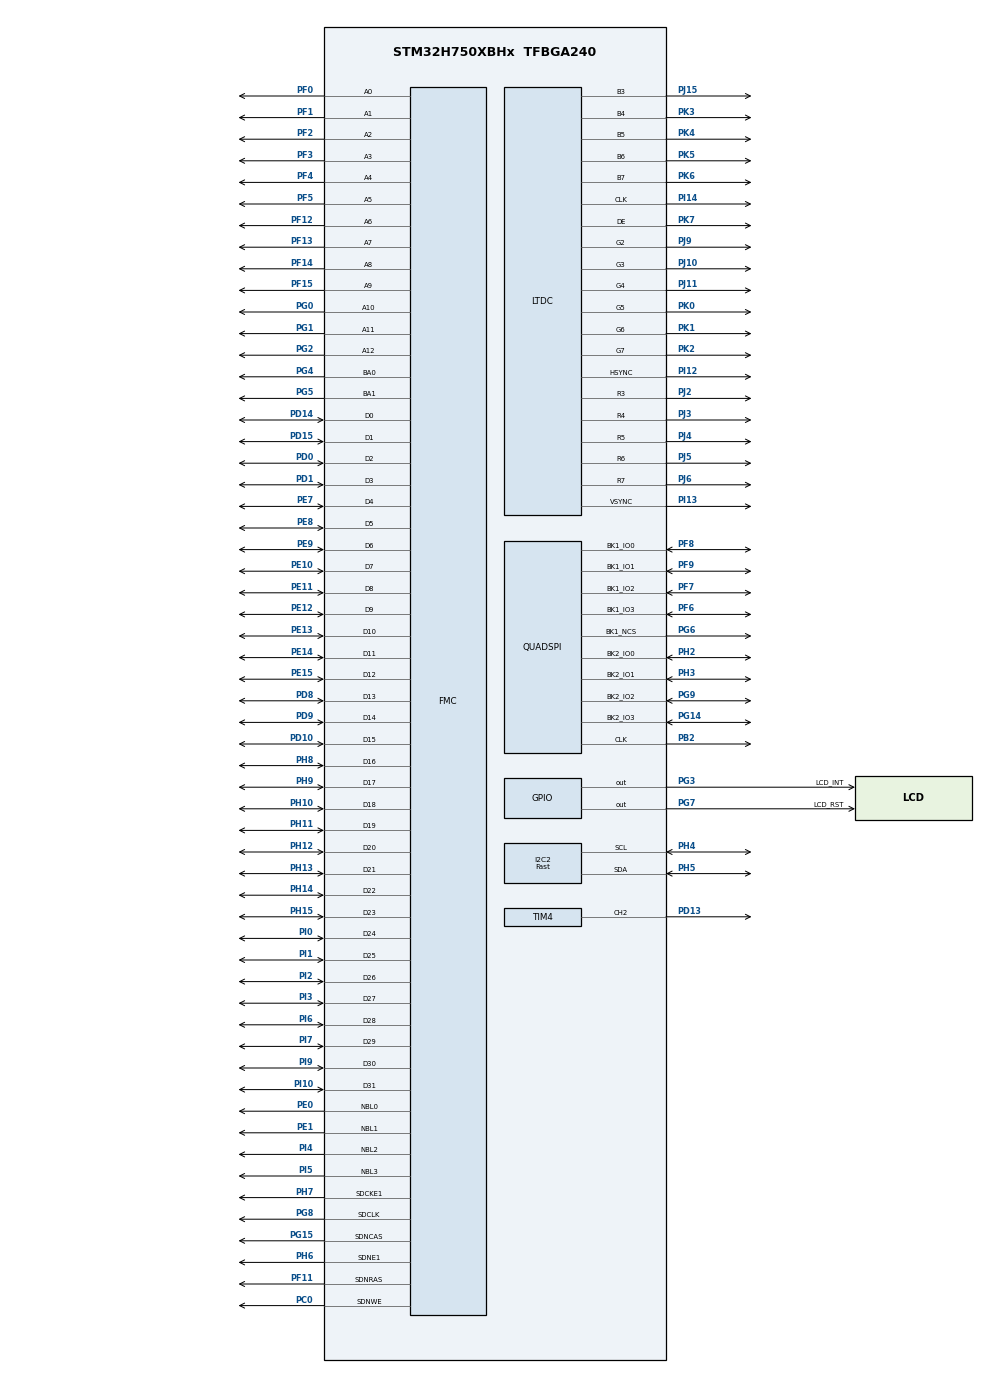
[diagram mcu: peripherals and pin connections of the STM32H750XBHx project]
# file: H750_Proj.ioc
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CORTEX_M7.AccessPermission-Cortex_Memory_Protection_Unit_Region0_Settings=MPU_REGION_FULL_ACCESS
CORTEX_M7.AccessPermission-Cortex_Memory_Protection_Unit_Region1_Settings=MPU_REGION_FULL_ACCESS
CORTEX_M7.AccessPermission-Cortex_Memory_Protection_Unit_Region2_Settings=MPU_REGION_FULL_ACCESS
CORTEX_M7.AccessPermission-Cortex_Memory_Protection_Unit_Region3_Settings=MPU_REGION_FULL_ACCESS
CORTEX_M7.AccessPermission-Cortex_Memory_Protection_Unit_Region4_Settings=MPU_REGION_FULL_ACCESS
CORTEX_M7.AccessPermission-Cortex_Memory_Protection_Unit_Region5_Settings=MPU_REGION_FULL_ACCESS
CORTEX_M7.BaseAddress-Cortex_Memory_Protection_Unit_Region0_Settings=0x20000000
CORTEX_M7.BaseAddress-Cortex_Memory_Protection_Unit_Region1_Settings=0x24000000
CORTEX_M7.BaseAddress-Cortex_Memory_Protection_Unit_Region2_Settings=0x0
CORTEX_M7.BaseAddress-Cortex_Memory_Protection_Unit_Region3_Settings=0x38000000
CORTEX_M7.BaseAddress-Cortex_Memory_Protection_Unit_Region4_Settings=0x60000000
CORTEX_M7.BaseAddress-Cortex_Memory_Protection_Unit_Region5_Settings=0xD0000000
CORTEX_M7.CPU_DCache=Enabled
CORTEX_M7.CPU_ICache=Enabled
CORTEX_M7.Enable-Cortex_Memory_Protection_Unit_Region0_Settings=MPU_REGION_ENABLE
CORTEX_M7.Enable-Cortex_Memory_Protection_Unit_Region1_Settings=MPU_REGION_ENABLE
CORTEX_M7.Enable-Cortex_Memory_Protection_Unit_Region2_Settings=MPU_REGION_ENABLE
CORTEX_M7.Enable-Cortex_Memory_Protection_Unit_Region3_Settings=MPU_REGION_ENABLE
CORTEX_M7.Enable-Cortex_Memory_Protection_Unit_Region4_Settings=MPU_REGION_ENABLE
CORTEX_M7.Enable-Cortex_Memory_Protection_Unit_Region5_Settings=MPU_REGION_ENABLE
CORTEX_M7.IsBufferable-Cortex_Memory_Protection_Unit_Region0_Settings=MPU_ACCESS_BUFFERABLE
CORTEX_M7.IsBufferable-Cortex_Memory_Protection_Unit_Region1_Settings=MPU_ACCESS_BUFFERABLE
CORTEX_M7.IsBufferable-Cortex_Memory_Protection_Unit_Region2_Settings=MPU_ACCESS_BUFFERABLE
CORTEX_M7.IsBufferable-Cortex_Memory_Protection_Unit_Region3_Settings=MPU_ACCESS_BUFFERABLE
CORTEX_M7.IsBufferable-Cortex_Memory_Protection_Unit_Region5_Settings=MPU_ACCESS_BUFFERABLE
CORTEX_M7.IsCacheable-Cortex_Memory_Protection_Unit_Region0_Settings=MPU_ACCESS_CACHEABLE
CORTEX_M7.IsCacheable-Cortex_Memory_Protection_Unit_Region1_Settings=MPU_ACCESS_CACHEABLE
CORTEX_M7.IsCacheable-Cortex_Memory_Protection_Unit_Region2_Settings=MPU_ACCESS_CACHEABLE
CORTEX_M7.IsCacheable-Cortex_Memory_Protection_Unit_Region5_Settings=MPU_ACCESS_CACHEABLE
CORTEX_M7.MPU_Control=MPU_PRIVILEGED_DEFAULT
CORTEX_M7.Size-Cortex_Memory_Protection_Unit_Region0_Settings=MPU_REGION_SIZE_128KB
CORTEX_M7.Size-Cortex_Memory_Protection_Unit_Region1_Settings=MPU_REGION_SIZE_512KB
CORTEX_M7.Size-Cortex_Memory_Protection_Unit_Region2_Settings=MPU_REGION_SIZE_512KB
CORTEX_M7.Size-Cortex_Memory_Protection_Unit_Region3_Settings=MPU_REGION_SIZE_64KB
CORTEX_M7.Size-Cortex_Memory_Protection_Unit_Region4_Settings=MPU_REGION_SIZE_64MB
CORTEX_M7.Size-Cortex_Memory_Protection_Unit_Region5_Settings=MPU_REGION_SIZE_64MB
DMA2D.ColorMode=DMA2D_OUTPUT_RGB565
FMC.CASLatency1=FMC_SDRAM_CAS_LATENCY_3
FMC.ColumnBitsNumber1=FMC_SDRAM_COLUMN_BITS_NUM_9
FMC.ExitSelfRefreshDelay1=8
FMC.LoadToActiveDelay1=2
FMC.RCDDelay1=2
FMC.RPDelay1=2
FMC.RPDelay2=2
FMC.ReadBurst1=FMC_SDRAM_RBURST_ENABLE
FMC.ReadBurst2=FMC_SDRAM_RBURST_ENABLE
FMC.ReadPipeDelay1=FMC_SDRAM_RPIPE_DELAY_1
FMC.ReadPipeDelay2=FMC_SDRAM_RPIPE_DELAY_1
FMC.RowCycleDelay1=8
FMC.RowCycleDelay2=8
FMC.SDClockPeriod1=FMC_SDRAM_CLOCK_PERIOD_2
FMC.SDClockPeriod2=FMC_SDRAM_CLOCK_PERIOD_2
FMC.SelfRefreshTime1=5
FMC.WriteRecoveryTime1=4
FREERTOS.Queues01=GuiQueue,16,uint16_t,0,Dynamic,NULL,NULL;myQueue,16,uint16_t,0,Dynamic,NULL,NULL
FREERTOS.Tasks01=defaultTask,0,2048,StartDefaultTask,Default,NULL,Dynamic,NULL,NULL;MessageTask,0,512,StartMessageTask,Default,NULL,Dynamic,NULL,NULL
FREERTOS.configTOTAL_HEAP_SIZE=32768
FREERTOS.configUSE_APPLICATION_TASK_TAG=1
I2C2.I2C_Speed_Mode=I2C_Fast
I2C2.Timing=0x00B03FDB
LTDC.ActiveW=480
LTDC.Alpha_L0=255
LTDC.FBStartAdress_L0=0xD0000000
LTDC.HBP=43
LTDC.HFP=8
LTDC.HSync=2
LTDC.ImageHeight_L0=480
LTDC.ImageWidth_L0=480
LTDC.Layers=0
LTDC.PCPolarity=LTDC_PCPOLARITY_IIPC
LTDC.PixelFormat_L0=LTDC_PIXEL_FORMAT_RGB565
LTDC.VBP=15
LTDC.VFP=12
LTDC.VSync=10
LTDC.WindowX1_L0=480
LTDC.WindowY1_L0=480
Mcu.Family=STM32H7
Mcu.Name=STM32H750XBHx
Mcu.Package=TFBGA240
NVIC.DMA2D_IRQn=true\:5\:0\:false\:false\:true\:true\:true\:true
NVIC.LTDC_IRQn=true\:5\:0\:false\:false\:true\:true\:true\:true
NVIC.PriorityGroup=NVIC_PRIORITYGROUP_4
NVIC.QUADSPI_IRQn=true\:5\:0\:false\:false\:true\:true\:true\:true
NVIC.TIM7_IRQn=true\:0\:0\:false\:false\:true\:false\:false\:true
NVIC.TimeBase=TIM7_IRQn
NVIC.TimeBaseIP=TIM7
PB2.GPIO_Speed=GPIO_SPEED_FREQ_VERY_HIGH
PB2.Mode=Dual_Bank
PB2.Signal=QUADSPI_CLK
PB2.Stacked=true
PC0.Signal=FMC_SDNWE
PC0.Stacked=true
PD0.Signal=FMC_D2_DA2
PD0.Stacked=true
PD1.Signal=FMC_D3_DA3
PD1.Stacked=true
PD10.Signal=FMC_D15_DA15
PD10.Stacked=true
PD13.Signal=S_TIM4_CH2
PD14.Signal=FMC_D0_DA0
PD14.Stacked=true
PD15.Signal=FMC_D1_DA1
PD15.Stacked=true
PD8.Signal=FMC_D13_DA13
PD8.Stacked=true
PD9.Signal=FMC_D14_DA14
PD9.Stacked=true
PE0.Signal=FMC_NBL0
PE0.Stacked=true
PE1.Signal=FMC_NBL1
PE1.Stacked=true
PE10.Signal=FMC_D7_DA7
PE10.Stacked=true
PE11.Signal=FMC_D8_DA8
PE11.Stacked=true
PE12.Signal=FMC_D9_DA9
PE12.Stacked=true
PE13.Signal=FMC_D10_DA10
PE13.Stacked=true
PE14.Signal=FMC_D11_DA11
PE14.Stacked=true
PE15.Signal=FMC_D12_DA12
PE15.Stacked=true
PE7.Signal=FMC_D4_DA4
PE7.Stacked=true
PE8.Signal=FMC_D5_DA5
PE8.Stacked=true
PE9.Signal=FMC_D6_DA6
PE9.Stacked=true
PF0.Signal=FMC_A0
PF0.Stacked=true
PF1.Signal=FMC_A1
PF1.Stacked=true
PF11.Signal=FMC_SDNRAS
PF11.Stacked=true
PF12.Signal=FMC_A6
PF12.Stacked=true
PF13.Signal=FMC_A7
PF13.Stacked=true
PF14.Signal=FMC_A8
PF14.Stacked=true
PF15.Signal=FMC_A9
PF15.Stacked=true
PF2.Signal=FMC_A2
PF2.Stacked=true
PF3.Signal=FMC_A3
PF3.Stacked=true
PF4.Signal=FMC_A4
PF4.Stacked=true
PF5.Signal=FMC_A5
PF5.Stacked=true
PF6.GPIO_Speed=GPIO_SPEED_FREQ_VERY_HIGH
PF6.Mode=Dual_Bank
PF6.Signal=QUADSPI_BK1_IO3
PF6.Stacked=true
PF7.GPIO_Speed=GPIO_SPEED_FREQ_VERY_HIGH
PF7.Mode=Dual_Bank
PF7.Signal=QUADSPI_BK1_IO2
PF7.Stacked=true
PF8.GPIO_Speed=GPIO_SPEED_FREQ_VERY_HIGH
PF8.Mode=Dual_Bank
PF8.Signal=QUADSPI_BK1_IO0
PF8.Stacked=true
PF9.GPIO_Speed=GPIO_SPEED_FREQ_VERY_HIGH
PF9.Mode=Dual_Bank
PF9.Signal=QUADSPI_BK1_IO1
PF9.Stacked=true
PG0.Signal=FMC_A10
PG0.Stacked=true
PG1.Signal=FMC_A11
PG1.Stacked=true
PG14.GPIO_Speed=GPIO_SPEED_FREQ_VERY_HIGH
PG14.Mode=Dual_Bank
PG14.Signal=QUADSPI_BK2_IO3
PG14.Stacked=true
PG15.Signal=FMC_SDNCAS
PG15.Stacked=true
PG2.Signal=FMC_A12
PG2.Stacked=true
PG3.GPIO_Label=LCD_INT
PG3.Signal=GPIO_Output
PG4.Signal=FMC_A14_BA0
PG4.Stacked=true
PG5.Signal=FMC_A15_BA1
PG5.Stacked=true
PG6.GPIO_Speed=GPIO_SPEED_FREQ_VERY_HIGH
PG6.Mode=Enable Chip Select 1 for both banks
PG6.Signal=QUADSPI_BK1_NCS
PG6.Stacked=true
PG7.GPIO_Label=LCD_RST
PG7.Signal=GPIO_Output
PG8.Signal=FMC_SDCLK
PG8.Stacked=true
PG9.GPIO_Speed=GPIO_SPEED_FREQ_VERY_HIGH
PG9.Mode=Dual_Bank
PG9.Signal=QUADSPI_BK2_IO2
PG9.Stacked=true
PH0-OSC_IN\ (PH0).Mode=HSE-External-Oscillator
PH0-OSC_IN\ (PH0).Signal=RCC_OSC_IN
PH1-OSC_OUT\ (PH1).Mode=HSE-External-Oscillator
PH1-OSC_OUT\ (PH1).Signal=RCC_OSC_OUT
PH10.Signal=FMC_D18
PH10.Stacked=true
PH11.Signal=FMC_D19
PH11.Stacked=true
PH12.Signal=FMC_D20
PH12.Stacked=true
PH13.Signal=FMC_D21
PH14.Signal=FMC_D22
PH15.Signal=FMC_D23
PH2.GPIO_Speed=GPIO_SPEED_FREQ_VERY_HIGH
PH2.Mode=Dual_Bank
PH2.Signal=QUADSPI_BK2_IO0
PH2.Stacked=true
PH3.GPIO_Speed=GPIO_SPEED_FREQ_VERY_HIGH
PH3.Mode=Dual_Bank
PH3.Signal=QUADSPI_BK2_IO1
PH3.Stacked=true
PH4.Mode=I2C
PH4.Signal=I2C2_SCL
PH5.Mode=I2C
PH5.Signal=I2C2_SDA
PH6.Mode=SdramChipSelect2_1
PH6.Signal=FMC_SDNE1
PH6.Stacked=true
PH7.Mode=SdramChipSelect2_1
PH7.Signal=FMC_SDCKE1
PH7.Stacked=true
PH8.Signal=FMC_D16
PH8.Stacked=true
PH9.Signal=FMC_D17
PH9.Stacked=true
PI0.Signal=FMC_D24
PI1.Signal=FMC_D25
PI10.Signal=FMC_D31
PI12.Mode=RGB565
PI12.Signal=LTDC_HSYNC
PI12.Stacked=true
PI13.Mode=RGB565
PI13.Signal=LTDC_VSYNC
PI13.Stacked=true
PI14.Mode=RGB565
PI14.Signal=LTDC_CLK
PI14.Stacked=true
PI2.Signal=FMC_D26
PI3.Signal=FMC_D27
PI4.Signal=FMC_NBL2
PI4.Stacked=true
PI5.Signal=FMC_NBL3
PI5.Stacked=true
PI6.Signal=FMC_D28
PI7.Signal=FMC_D29
PI9.Signal=FMC_D30
PJ10.Mode=RGB565
PJ10.Signal=LTDC_G3
PJ10.Stacked=true
PJ11.Mode=RGB565
PJ11.Signal=LTDC_G4
PJ11.Stacked=true
PJ15.Mode=RGB565
PJ15.Signal=LTDC_B3
PJ15.Stacked=true
PJ2.Mode=RGB565
PJ2.Signal=LTDC_R3
PJ2.Stacked=true
PJ3.Mode=RGB565
PJ3.Signal=LTDC_R4
PJ3.Stacked=true
PJ4.Mode=RGB565
PJ4.Signal=LTDC_R5
PJ4.Stacked=true
PJ5.Mode=RGB565
PJ5.Signal=LTDC_R6
PJ5.Stacked=true
PJ6.Mode=RGB565
PJ6.Signal=LTDC_R7
PJ6.Stacked=true
PJ9.Mode=RGB565
PJ9.Signal=LTDC_G2
PJ9.Stacked=true
PK0.Mode=RGB565
PK0.Signal=LTDC_G5
PK0.Stacked=true
PK1.Mode=RGB565
PK1.Signal=LTDC_G6
PK1.Stacked=true
PK2.Mode=RGB565
PK2.Signal=LTDC_G7
PK2.Stacked=true
PK3.Mode=RGB565
PK3.Signal=LTDC_B4
PK3.Stacked=true
PK4.Mode=RGB565
PK4.Signal=LTDC_B5
PK4.Stacked=true
PK5.Mode=RGB565
PK5.Signal=LTDC_B6
PK5.Stacked=true
PK6.Mode=RGB565
PK6.Signal=LTDC_B7
PK6.Stacked=true
PK7.Mode=RGB565
PK7.Signal=LTDC_DE
PK7.Stacked=true
ProjectManager.HeapSize=0x400
ProjectManager.StackSize=0x800
ProjectManager.TargetToolchain=MDK-ARM V5.27
QUADSPI.ChipSelectHighTime=QSPI_CS_HIGH_TIME_4_CYCLE
QUADSPI.ClockPrescaler=2
QUADSPI.FifoThreshold=8
QUADSPI.FlashSize=25
QUADSPI.SampleShifting=QSPI_SAMPLE_SHIFTING_NONE
RCC.ADCFreq_Value=50390625
RCC.APB1Freq_Value=120000000
RCC.APB2Freq_Value=120000000
RCC.APB3Freq_Value=120000000
RCC.APB4Freq_Value=120000000
RCC.CortexFreq_Value=480000000
RCC.D1PPRE=RCC_APB3_DIV2
RCC.D2PPRE1=RCC_APB1_DIV2
RCC.D2PPRE2=RCC_APB2_DIV2
RCC.D3PPRE=RCC_APB4_DIV2
RCC.DIVM1=5
RCC.DIVM3=31
RCC.DIVN1=192
RCC.DIVN3=138
RCC.DIVR3=6
RCC.HCLKFreq_Value=240000000
RCC.HPRE=RCC_HCLK_DIV2
RCC.PLLSourceVirtual=RCC_PLLSOURCE_HSE
RCC.SYSCLKFreq_VALUE=480000000
RCC.SYSCLKSource=RCC_SYSCLKSOURCE_PLLCLK
RCC.USBFreq_Value=480000000
SH.FMC_A0.0=FMC_A0,13b-sda1
SH.FMC_A1.0=FMC_A1,13b-sda1
SH.FMC_A10.0=FMC_A10,13b-sda1
SH.FMC_A11.0=FMC_A11,13b-sda1
SH.FMC_A12.0=FMC_A12,13b-sda1
SH.FMC_A14_BA0.0=FMC_BA0,FourSdramBanks1
SH.FMC_A15_BA1.0=FMC_BA1,FourSdramBanks1
SH.FMC_A2.0=FMC_A2,13b-sda1
SH.FMC_A3.0=FMC_A3,13b-sda1
SH.FMC_A4.0=FMC_A4,13b-sda1
SH.FMC_A5.0=FMC_A5,13b-sda1
SH.FMC_A6.0=FMC_A6,13b-sda1
SH.FMC_A7.0=FMC_A7,13b-sda1
SH.FMC_A8.0=FMC_A8,13b-sda1
SH.FMC_A9.0=FMC_A9,13b-sda1
SH.FMC_D0_DA0.0=FMC_D0,sd-32b-d1
SH.FMC_D10_DA10.0=FMC_D10,sd-32b-d1
SH.FMC_D11_DA11.0=FMC_D11,sd-32b-d1
SH.FMC_D12_DA12.0=FMC_D12,sd-32b-d1
SH.FMC_D13_DA13.0=FMC_D13,sd-32b-d1
SH.FMC_D14_DA14.0=FMC_D14,sd-32b-d1
SH.FMC_D15_DA15.0=FMC_D15,sd-32b-d1
SH.FMC_D16.0=FMC_D16,sd-32b-d1
SH.FMC_D17.0=FMC_D17,sd-32b-d1
SH.FMC_D18.0=FMC_D18,sd-32b-d1
SH.FMC_D19.0=FMC_D19,sd-32b-d1
SH.FMC_D1_DA1.0=FMC_D1,sd-32b-d1
SH.FMC_D20.0=FMC_D20,sd-32b-d1
SH.FMC_D21.0=FMC_D21,sd-32b-d1
SH.FMC_D22.0=FMC_D22,sd-32b-d1
SH.FMC_D23.0=FMC_D23,sd-32b-d1
SH.FMC_D24.0=FMC_D24,sd-32b-d1
SH.FMC_D25.0=FMC_D25,sd-32b-d1
SH.FMC_D26.0=FMC_D26,sd-32b-d1
SH.FMC_D27.0=FMC_D27,sd-32b-d1
SH.FMC_D28.0=FMC_D28,sd-32b-d1
SH.FMC_D29.0=FMC_D29,sd-32b-d1
SH.FMC_D2_DA2.0=FMC_D2,sd-32b-d1
SH.FMC_D30.0=FMC_D30,sd-32b-d1
SH.FMC_D31.0=FMC_D31,sd-32b-d1
SH.FMC_D3_DA3.0=FMC_D3,sd-32b-d1
SH.FMC_D4_DA4.0=FMC_D4,sd-32b-d1
SH.FMC_D5_DA5.0=FMC_D5,sd-32b-d1
SH.FMC_D6_DA6.0=FMC_D6,sd-32b-d1
SH.FMC_D7_DA7.0=FMC_D7,sd-32b-d1
SH.FMC_D8_DA8.0=FMC_D8,sd-32b-d1
SH.FMC_D9_DA9.0=FMC_D9,sd-32b-d1
SH.FMC_NBL0.0=FMC_NBL0,Sd4ByteEnable1
SH.FMC_NBL1.0=FMC_NBL1,Sd4ByteEnable1
SH.FMC_NBL2.0=FMC_NBL2,Sd4ByteEnable1
SH.FMC_NBL3.0=FMC_NBL3,Sd4ByteEnable1
SH.FMC_SDCLK.0=FMC_SDCLK,13b-sda1
SH.FMC_SDNCAS.0=FMC_SDNCAS,13b-sda1
SH.FMC_SDNRAS.0=FMC_SDNRAS,13b-sda1
SH.FMC_SDNWE.0=FMC_SDNWE,13b-sda1
SH.S_TIM4_CH2.0=TIM4_CH2,PWM Generation2 CH2
STMicroelectronics.X-CUBE-TOUCHGFX.4.13.0.ApplicationCcGraphicsJjApplication=TouchGFXOoGenerator
STMicroelectronics.X-CUBE-TOUCHGFX.4.13.0.tgfx_address1=0xD0000000
STMicroelectronics.X-CUBE-TOUCHGFX.4.13.0.tgfx_address2=0xD0070800
STMicroelectronics.X-CUBE-TOUCHGFX.4.13.0.tgfx_buffering_strategy=Double
STMicroelectronics.X-CUBE-TOUCHGFX.4.13.0.tgfx_display_interface=disp_ltdc
STMicroelectronics.X-CUBE-TOUCHGFX.4.13.0.tgfx_hardware_accelerator=dma_2d
STMicroelectronics.X-CUBE-TOUCHGFX.4.13.0.tgfx_location=By Address
STMicroelectronics.X-CUBE-TOUCHGFX.4.13.0.tgfx_vsync=vsync_ltdc
TIM4.Channel-PWM\ Generation2\ CH2=TIM_CHANNEL_2
TIM4.OCPolarity_2=TIM_OCPOLARITY_LOW
TIM4.Period=999
TIM4.Prescaler=2399
VP_CRC_VS_CRC.Mode=CRC_Activate
VP_DMA2D_VS_DMA2D.Mode=DMA2D_Activate
VP_FREERTOS_VS_CMSIS_V1.Mode=CMSIS_V1
VP_STMicroelectronics.X-CUBE-TOUCHGFX_VS_GraphicsJjApplication_4.13.0.Mode=GraphicsJjApplication
VP_SYS_VS_tim7.Mode=TIM7
VP_TIM4_VS_ClockSourceINT.Mode=Internal
board=custom

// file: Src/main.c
/* USER CODE BEGIN Header */
/**
  ******************************************************************************
  * @file           : main.c
  * @brief          : Main program body
  ******************************************************************************
  * @attention
  *
  * <h2><center>&copy; Copyright (c) 2020 STMicroelectronics.
  * All rights reserved.</center></h2>
  *
  * This software component is licensed by ST under Ultimate Liberty license
  * SLA0044, the "License"; You may not use this file except in compliance with
  * the License. You may obtain a copy of the License at:
  *                             www.st.com/SLA0044
  *
  ******************************************************************************
  */
/* USER CODE END Header */

#include "main.h"
#include "cmsis_os.h"
#include "crc.h"
#include "dma2d.h"
#include "i2c.h"
#include "ltdc.h"
#include "quadspi.h"
#include "tim.h"
#include "gpio.h"
#include "fmc.h"
#include "app_touchgfx.h"

void SystemClock_Config(void);
static void MPU_Config(void);
void MX_FREERTOS_Init(void);

int main(void)
{

  /* MPU Configuration--------------------------------------------------------*/
  MPU_Config();

  /* Enable I-Cache---------------------------------------------------------*/
  SCB_EnableICache();

  /* Enable D-Cache---------------------------------------------------------*/
  SCB_EnableDCache();

  /* MCU Configuration--------------------------------------------------------*/

  /* Reset of all peripherals, Initializes the Flash interface and the Systick. */
  HAL_Init();

  /* Configure the system clock */
  SystemClock_Config();

  /* Initialize all configured peripherals */
  MX_GPIO_Init();
  MX_CRC_Init();
  MX_DMA2D_Init();
  MX_FMC_Init();
  MX_I2C2_Init();
  MX_LTDC_Init();
  MX_QUADSPI_Init();
  MX_TIM4_Init();
  MX_TouchGFX_Init();
  /* USER CODE BEGIN 2 */
  SDRAM_InitSequence();

  HAL_GPIO_WritePin(GPIOG, LCD_RST_Pin, GPIO_PIN_SET);
  HAL_TIM_PWM_Start(&htim4,TIM_CHANNEL_2);
  __HAL_TIM_SET_COMPARE(&htim4,TIM_CHANNEL_2, 500);

  /* USER CODE END 2 */

  /* Call init function for freertos objects (in freertos.c) */
  MX_FREERTOS_Init();
  /* Start scheduler */
  osKernelStart();

  /* We should never get here as control is now taken by the scheduler */
  /* Infinite loop */
  while (1)
  {

  }
}

void SystemClock_Config(void)
{
  RCC_OscInitTypeDef RCC_OscInitStruct = {0};
  RCC_ClkInitTypeDef RCC_ClkInitStruct = {0};
  RCC_PeriphCLKInitTypeDef PeriphClkInitStruct = {0};

  /** Supply configuration update enable
  */
  HAL_PWREx_ConfigSupply(PWR_LDO_SUPPLY);
  /** Configure the main internal regulator output voltage
  */
  __HAL_PWR_VOLTAGESCALING_CONFIG(PWR_REGULATOR_VOLTAGE_SCALE0);

  while(!__HAL_PWR_GET_FLAG(PWR_FLAG_VOSRDY)) {}
  /** Macro to configure the PLL clock source
  */
  __HAL_RCC_PLL_PLLSOURCE_CONFIG(RCC_PLLSOURCE_HSE);
  /** Initializes the CPU, AHB and APB busses clocks
  */
  RCC_OscInitStruct.OscillatorType = RCC_OSCILLATORTYPE_HSE;
  RCC_OscInitStruct.HSEState = RCC_HSE_ON;
  RCC_OscInitStruct.PLL.PLLState = RCC_PLL_ON;
  RCC_OscInitStruct.PLL.PLLSource = RCC_PLLSOURCE_HSE;
  RCC_OscInitStruct.PLL.PLLM = 5;
  RCC_OscInitStruct.PLL.PLLN = 192;
  RCC_OscInitStruct.PLL.PLLP = 2;
  RCC_OscInitStruct.PLL.PLLQ = 2;
  RCC_OscInitStruct.PLL.PLLR = 2;
  RCC_OscInitStruct.PLL.PLLRGE = RCC_PLL1VCIRANGE_2;
  RCC_OscInitStruct.PLL.PLLVCOSEL = RCC_PLL1VCOWIDE;
  RCC_OscInitStruct.PLL.PLLFRACN = 0;
  if (HAL_RCC_OscConfig(&RCC_OscInitStruct) != HAL_OK)
  {
    Error_Handler();
  }
  /** Initializes the CPU, AHB and APB busses clocks
  */
  RCC_ClkInitStruct.ClockType = RCC_CLOCKTYPE_HCLK|RCC_CLOCKTYPE_SYSCLK
                              |RCC_CLOCKTYPE_PCLK1|RCC_CLOCKTYPE_PCLK2
                              |RCC_CLOCKTYPE_D3PCLK1|RCC_CLOCKTYPE_D1PCLK1;
  RCC_ClkInitStruct.SYSCLKSource = RCC_SYSCLKSOURCE_PLLCLK;
  RCC_ClkInitStruct.SYSCLKDivider = RCC_SYSCLK_DIV1;
  RCC_ClkInitStruct.AHBCLKDivider = RCC_HCLK_DIV2;
  RCC_ClkInitStruct.APB3CLKDivider = RCC_APB3_DIV2;
  RCC_ClkInitStruct.APB1CLKDivider = RCC_APB1_DIV2;
  RCC_ClkInitStruct.APB2CLKDivider = RCC_APB2_DIV2;
  RCC_ClkInitStruct.APB4CLKDivider = RCC_APB4_DIV2;

  if (HAL_RCC_ClockConfig(&RCC_ClkInitStruct, FLASH_LATENCY_4) != HAL_OK)
  {
    Error_Handler();
  }
  PeriphClkInitStruct.PeriphClockSelection = RCC_PERIPHCLK_LTDC|RCC_PERIPHCLK_I2C2
                              |RCC_PERIPHCLK_QSPI|RCC_PERIPHCLK_FMC;
  PeriphClkInitStruct.PLL3.PLL3M = 31;
  PeriphClkInitStruct.PLL3.PLL3N = 138;
  PeriphClkInitStruct.PLL3.PLL3P = 2;
  PeriphClkInitStruct.PLL3.PLL3Q = 2;
  PeriphClkInitStruct.PLL3.PLL3R = 6;
  PeriphClkInitStruct.PLL3.PLL3RGE = RCC_PLL3VCIRANGE_3;
  PeriphClkInitStruct.PLL3.PLL3VCOSEL = RCC_PLL3VCOWIDE;
  PeriphClkInitStruct.PLL3.PLL3FRACN = 0;
  PeriphClkInitStruct.FmcClockSelection = RCC_FMCCLKSOURCE_D1HCLK;
  PeriphClkInitStruct.QspiClockSelection = RCC_QSPICLKSOURCE_D1HCLK;
  PeriphClkInitStruct.I2c123ClockSelection = RCC_I2C123CLKSOURCE_D2PCLK1;
  if (HAL_RCCEx_PeriphCLKConfig(&PeriphClkInitStruct) != HAL_OK)
  {
    Error_Handler();
  }
}

/* MPU Configuration */

void MPU_Config(void)
{
  MPU_Region_InitTypeDef MPU_InitStruct = {0};

  /* Disables the MPU */
  HAL_MPU_Disable();
  /** Initializes and configures the Region and the memory to be protected
  */
  MPU_InitStruct.Enable = MPU_REGION_ENABLE;
  MPU_InitStruct.Number = MPU_REGION_NUMBER0;
  MPU_InitStruct.BaseAddress = 0x20000000;
  MPU_InitStruct.Size = MPU_REGION_SIZE_128KB;
  MPU_InitStruct.SubRegionDisable = 0x0;
  MPU_InitStruct.TypeExtField = MPU_TEX_LEVEL0;
  MPU_InitStruct.AccessPermission = MPU_REGION_FULL_ACCESS;
  MPU_InitStruct.DisableExec = MPU_INSTRUCTION_ACCESS_ENABLE;
  MPU_InitStruct.IsShareable = MPU_ACCESS_NOT_SHAREABLE;
  MPU_InitStruct.IsCacheable = MPU_ACCESS_CACHEABLE;
  MPU_InitStruct.IsBufferable = MPU_ACCESS_BUFFERABLE;

  HAL_MPU_ConfigRegion(&MPU_InitStruct);
  /** Initializes and configures the Region and the memory to be protected
  */
  MPU_InitStruct.Enable = MPU_REGION_ENABLE;
  MPU_InitStruct.Number = MPU_REGION_NUMBER1;
  MPU_InitStruct.BaseAddress = 0x24000000;
  MPU_InitStruct.Size = MPU_REGION_SIZE_512KB;
  MPU_InitStruct.SubRegionDisable = 0x0;
  MPU_InitStruct.TypeExtField = MPU_TEX_LEVEL0;
  MPU_InitStruct.AccessPermission = MPU_REGION_FULL_ACCESS;
  MPU_InitStruct.DisableExec = MPU_INSTRUCTION_ACCESS_ENABLE;
  MPU_InitStruct.IsShareable = MPU_ACCESS_NOT_SHAREABLE;
  MPU_InitStruct.IsCacheable = MPU_ACCESS_CACHEABLE;
  MPU_InitStruct.IsBufferable = MPU_ACCESS_BUFFERABLE;

  HAL_MPU_ConfigRegion(&MPU_InitStruct);
  /** Initializes and configures the Region and the memory to be protected
  */
  MPU_InitStruct.Enable = MPU_REGION_ENABLE;
  MPU_InitStruct.Number = MPU_REGION_NUMBER2;
  MPU_InitStruct.BaseAddress = 0x0;
  MPU_InitStruct.Size = MPU_REGION_SIZE_512KB;
  MPU_InitStruct.SubRegionDisable = 0x0;
  MPU_InitStruct.TypeExtField = MPU_TEX_LEVEL0;
  MPU_InitStruct.AccessPermission = MPU_REGION_FULL_ACCESS;
  MPU_InitStruct.DisableExec = MPU_INSTRUCTION_ACCESS_ENABLE;
  MPU_InitStruct.IsShareable = MPU_ACCESS_NOT_SHAREABLE;
  MPU_InitStruct.IsCacheable = MPU_ACCESS_CACHEABLE;
  MPU_InitStruct.IsBufferable = MPU_ACCESS_BUFFERABLE;

  HAL_MPU_ConfigRegion(&MPU_InitStruct);
  /** Initializes and configures the Region and the memory to be protected
  */
  MPU_InitStruct.Enable = MPU_REGION_ENABLE;
  MPU_InitStruct.Number = MPU_REGION_NUMBER3;
  MPU_InitStruct.BaseAddress = 0x38000000;
  MPU_InitStruct.Size = MPU_REGION_SIZE_64KB;
  MPU_InitStruct.SubRegionDisable = 0x0;
  MPU_InitStruct.TypeExtField = MPU_TEX_LEVEL0;
  MPU_InitStruct.AccessPermission = MPU_REGION_FULL_ACCESS;
  MPU_InitStruct.DisableExec = MPU_INSTRUCTION_ACCESS_ENABLE;
  MPU_InitStruct.IsShareable = MPU_ACCESS_NOT_SHAREABLE;
  MPU_InitStruct.IsCacheable = MPU_ACCESS_NOT_CACHEABLE;
  MPU_InitStruct.IsBufferable = MPU_ACCESS_BUFFERABLE;

  HAL_MPU_ConfigRegion(&MPU_InitStruct);
  /** Initializes and configures the Region and the memory to be protected
  */
  MPU_InitStruct.Enable = MPU_REGION_ENABLE;
  MPU_InitStruct.Number = MPU_REGION_NUMBER4;
  MPU_InitStruct.BaseAddress = 0x60000000;
  MPU_InitStruct.Size = MPU_REGION_SIZE_64MB;
  MPU_InitStruct.SubRegionDisable = 0x0;
  MPU_InitStruct.TypeExtField = MPU_TEX_LEVEL0;
  MPU_InitStruct.AccessPermission = MPU_REGION_FULL_ACCESS;
  MPU_InitStruct.DisableExec = MPU_INSTRUCTION_ACCESS_ENABLE;
  MPU_InitStruct.IsShareable = MPU_ACCESS_NOT_SHAREABLE;
  MPU_InitStruct.IsCacheable = MPU_ACCESS_NOT_CACHEABLE;
  MPU_InitStruct.IsBufferable = MPU_ACCESS_NOT_BUFFERABLE;

  HAL_MPU_ConfigRegion(&MPU_InitStruct);
  /** Initializes and configures the Region and the memory to be protected
  */
  MPU_InitStruct.Enable = MPU_REGION_ENABLE;
  MPU_InitStruct.Number = MPU_REGION_NUMBER5;
  MPU_InitStruct.BaseAddress = 0xD0000000;
  MPU_InitStruct.Size = MPU_REGION_SIZE_64MB;
  MPU_InitStruct.SubRegionDisable = 0x0;
  MPU_InitStruct.TypeExtField = MPU_TEX_LEVEL0;
  MPU_InitStruct.AccessPermission = MPU_REGION_FULL_ACCESS;
  MPU_InitStruct.DisableExec = MPU_INSTRUCTION_ACCESS_ENABLE;
  MPU_InitStruct.IsShareable = MPU_ACCESS_NOT_SHAREABLE;
  MPU_InitStruct.IsCacheable = MPU_ACCESS_CACHEABLE;
  MPU_InitStruct.IsBufferable = MPU_ACCESS_BUFFERABLE;

  HAL_MPU_ConfigRegion(&MPU_InitStruct);
  /* Enables the MPU */
  HAL_MPU_Enable(MPU_PRIVILEGED_DEFAULT);

}
void HAL_TIM_PeriodElapsedCallback(TIM_HandleTypeDef *htim)
{
  if (htim->Instance == TIM7) {
    HAL_IncTick();
  }
}

void Error_Handler(void)
{
}

/************************ (C) COPYRIGHT STMicroelectronics *****END OF FILE****/

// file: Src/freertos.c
/* USER CODE BEGIN Header */
/**
  ******************************************************************************
  * File Name          : freertos.c
  * Description        : Code for freertos applications
  ******************************************************************************
  * @attention
  *
  * <h2><center>&copy; Copyright (c) 2020 STMicroelectronics.
  * All rights reserved.</center></h2>
  *
  * This software component is licensed by ST under Ultimate Liberty license
  * SLA0044, the "License"; You may not use this file except in compliance with
  * the License. You may obtain a copy of the License at:
  *                             www.st.com/SLA0044
  *
  ******************************************************************************
  */
/* USER CODE END Header */

#include "FreeRTOS.h"
#include "task.h"
#include "main.h"
#include "cmsis_os.h"

/* USER CODE BEGIN Includes */
#include "app_touchgfx.h"
/* USER CODE END Includes */

osThreadId defaultTaskHandle;
osThreadId MessageTaskHandle;
osMessageQId GuiQueueHandle;
osMessageQId myQueueHandle;

void StartDefaultTask(void const * argument);
void StartMessageTask(void const * argument);

void MX_FREERTOS_Init(void); /* (MISRA C 2004 rule 8.1) */

/* GetIdleTaskMemory prototype (linked to static allocation support) */
void vApplicationGetIdleTaskMemory( StaticTask_t **ppxIdleTaskTCBBuffer, StackType_t **ppxIdleTaskStackBuffer, uint32_t *pulIdleTaskStackSize );

/* USER CODE BEGIN GET_IDLE_TASK_MEMORY */
static StaticTask_t xIdleTaskTCBBuffer;
static StackType_t xIdleStack[configMINIMAL_STACK_SIZE];

void vApplicationGetIdleTaskMemory( StaticTask_t **ppxIdleTaskTCBBuffer, StackType_t **ppxIdleTaskStackBuffer, uint32_t *pulIdleTaskStackSize )
{
  *ppxIdleTaskTCBBuffer = &xIdleTaskTCBBuffer;
  *ppxIdleTaskStackBuffer = &xIdleStack[0];
  *pulIdleTaskStackSize = configMINIMAL_STACK_SIZE;
  /* place for user code */
}
/* USER CODE END GET_IDLE_TASK_MEMORY */

void MX_FREERTOS_Init(void) {

  /* Create the queue(s) */
  /* definition and creation of GuiQueue */
  osMessageQDef(GuiQueue, 16, uint16_t);
  GuiQueueHandle = osMessageCreate(osMessageQ(GuiQueue), NULL);

  /* definition and creation of myQueue */
  osMessageQDef(myQueue, 16, uint16_t);
  myQueueHandle = osMessageCreate(osMessageQ(myQueue), NULL);

  /* Create the thread(s) */
  /* definition and creation of defaultTask */
  osThreadDef(defaultTask, StartDefaultTask, osPriorityNormal, 0, 2048);
  defaultTaskHandle = osThreadCreate(osThread(defaultTask), NULL);

  /* definition and creation of MessageTask */
  osThreadDef(MessageTask, StartMessageTask, osPriorityNormal, 0, 512);
  MessageTaskHandle = osThreadCreate(osThread(MessageTask), NULL);

}

void StartDefaultTask(void const * argument)
{
  /* USER CODE BEGIN StartDefaultTask */
    MX_TouchGFX_Process();
  /* Infinite loop */
  for(;;)
  {
    osDelay(1);
  }
  /* USER CODE END StartDefaultTask */
}

void StartMessageTask(void const * argument)
{
  for(;;)
  {
    osDelay(1);
  }
}

/************************ (C) COPYRIGHT STMicroelectronics *****END OF FILE****/
